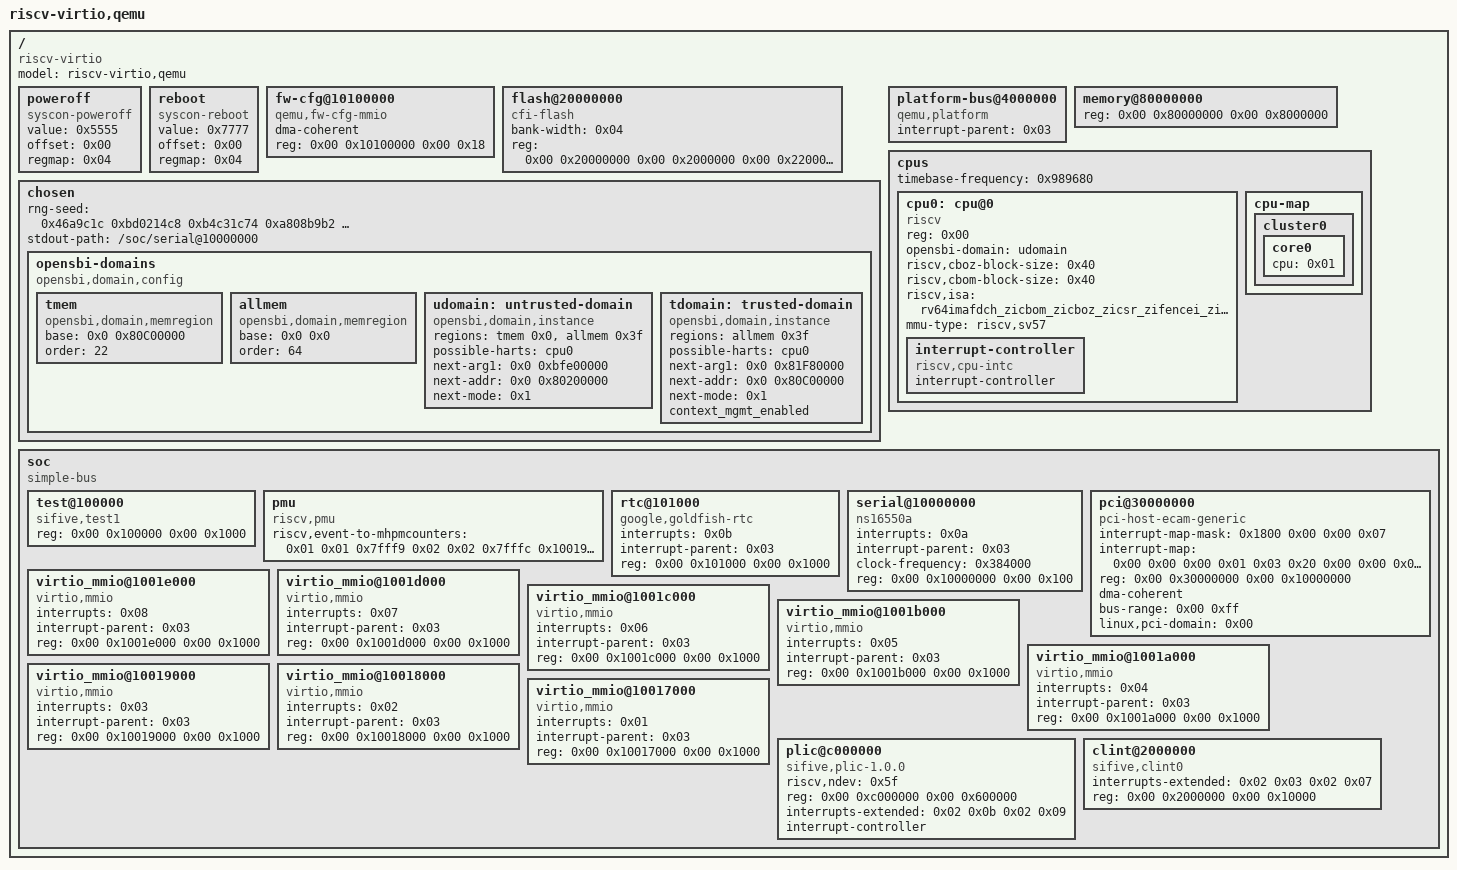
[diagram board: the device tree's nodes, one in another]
/dts-v1/;

/ {
	#address-cells = <0x02>;
	#size-cells = <0x02>;
	compatible = "riscv-virtio";
	model = "riscv-virtio,qemu";

	poweroff {
		value = <0x5555>;
		offset = <0x00>;
		regmap = <0x04>;
		compatible = "syscon-poweroff";
	};

	reboot {
		value = <0x7777>;
		offset = <0x00>;
		regmap = <0x04>;
		compatible = "syscon-reboot";
	};

	fw-cfg@10100000 {
		dma-coherent;
		reg = <0x00 0x10100000 0x00 0x18>;
		compatible = "qemu,fw-cfg-mmio";
	};

	flash@20000000 {
		bank-width = <0x04>;
		reg = <0x00 0x20000000 0x00 0x2000000 0x00 0x22000000 0x00 0x2000000>;
		compatible = "cfi-flash";
	};

	chosen {
		rng-seed = <0x46a9c1c 0xbd0214c8 0xb4c31c74 0xa808b9b2 0x50cb0d36 0x9aa9f04b 0x36ab14cc 0x835da7b>;
		stdout-path = "/soc/serial@10000000";
		opensbi-domains {
			compatible = "opensbi,domain,config";

			tmem: tmem {
				compatible = "opensbi,domain,memregion";
				base = <0x0 0x80C00000>;
				order = <22>;   // 4M
			};

			allmem: allmem {
				compatible = "opensbi,domain,memregion";
				base = <0x0 0x0>;
				order = <64>;
			};

			udomain: untrusted-domain {
				compatible = "opensbi,domain,instance";
				regions = <&tmem 0x0>, <&allmem 0x3f>;
				possible-harts = <&cpu0>;
				next-arg1 = <0x0 0xbfe00000>;
				next-addr = <0x0 0x80200000>;
				next-mode = <0x1>;
			};

			tdomain: trusted-domain {
				compatible = "opensbi,domain,instance";
				regions = <&allmem 0x3f>;
				possible-harts = <&cpu0>;
				next-arg1 = <0x0 0x81F80000>;
				next-addr = <0x0 0x80C00000>;
				next-mode = <0x1>;
                context_mgmt_enabled;
			};
		};
	};

	platform-bus@4000000 {
		interrupt-parent = <0x03>;
		ranges = <0x00 0x00 0x4000000 0x2000000>;
		#address-cells = <0x01>;
		#size-cells = <0x01>;
		compatible = "qemu,platform\0simple-bus";
	};

	memory@80000000 {
		device_type = "memory";
		reg = <0x00 0x80000000 0x00 0x8000000>;
	};

	cpus {
		#address-cells = <0x01>;
		#size-cells = <0x00>;
		timebase-frequency = <0x989680>;

		cpu0: cpu@0 {
			phandle = <0x01>;
			device_type = "cpu";
			reg = <0x00>;
			status = "okay";
			compatible = "riscv";
			opensbi-domain = <&udomain>;
			riscv,cboz-block-size = <0x40>;
			riscv,cbom-block-size = <0x40>;
			riscv,isa = "rv64imafdch_zicbom_zicboz_zicsr_zifencei_zihintpause_zawrs_zfa_zca_zcd_zba_zbb_zbc_zbs_sstc_svadu";
			mmu-type = "riscv,sv57";

			interrupt-controller {
				#interrupt-cells = <0x01>;
				interrupt-controller;
				compatible = "riscv,cpu-intc";
				phandle = <0x02>;
			};
		};

		cpu-map {

			cluster0 {

				core0 {
					cpu = <0x01>;
				};
			};
		};
	};

	soc {
		#address-cells = <0x02>;
		#size-cells = <0x02>;
		compatible = "simple-bus";
		ranges;

		test@100000 {
			phandle = <0x04>;
			reg = <0x00 0x100000 0x00 0x1000>;
			compatible = "sifive,test1\0sifive,test0\0syscon";
		};

		pmu {
			riscv,event-to-mhpmcounters = <0x01 0x01 0x7fff9 0x02 0x02 0x7fffc 0x10019 0x10019 0x7fff8 0x1001b 0x1001b 0x7fff8 0x10021 0x10021 0x7fff8>;
			compatible = "riscv,pmu";
		};

		rtc@101000 {
			interrupts = <0x0b>;
			interrupt-parent = <0x03>;
			reg = <0x00 0x101000 0x00 0x1000>;
			compatible = "google,goldfish-rtc";
		};

		serial@10000000 {
			interrupts = <0x0a>;
			interrupt-parent = <0x03>;
			clock-frequency = <0x384000>;
			reg = <0x00 0x10000000 0x00 0x100>;
			compatible = "ns16550a";
		};

		pci@30000000 {
			interrupt-map-mask = <0x1800 0x00 0x00 0x07>;
			interrupt-map = <0x00 0x00 0x00 0x01 0x03 0x20 0x00 0x00 0x00 0x02 0x03 0x21 0x00 0x00 0x00 0x03 0x03 0x22 0x00 0x00 0x00 0x04 0x03 0x23 0x800 0x00 0x00 0x01 0x03 0x21 0x800 0x00 0x00 0x02 0x03 0x22 0x800 0x00 0x00 0x03 0x03 0x23 0x800 0x00 0x00 0x04 0x03 0x20 0x1000 0x00 0x00 0x01 0x03 0x22 0x1000 0x00 0x00 0x02 0x03 0x23 0x1000 0x00 0x00 0x03 0x03 0x20 0x1000 0x00 0x00 0x04 0x03 0x21 0x1800 0x00 0x00 0x01 0x03 0x23 0x1800 0x00 0x00 0x02 0x03 0x20 0x1800 0x00 0x00 0x03 0x03 0x21 0x1800 0x00 0x00 0x04 0x03 0x22>;
			ranges = <0x1000000 0x00 0x00 0x00 0x3000000 0x00 0x10000 0x2000000 0x00 0x40000000 0x00 0x40000000 0x00 0x40000000 0x3000000 0x04 0x00 0x04 0x00 0x04 0x00>;
			reg = <0x00 0x30000000 0x00 0x10000000>;
			dma-coherent;
			bus-range = <0x00 0xff>;
			linux,pci-domain = <0x00>;
			device_type = "pci";
			compatible = "pci-host-ecam-generic";
			#size-cells = <0x02>;
			#interrupt-cells = <0x01>;
			#address-cells = <0x03>;
		};

		virtio_mmio@1001e000 {
			interrupts = <0x08>;
			interrupt-parent = <0x03>;
			reg = <0x00 0x1001e000 0x00 0x1000>;
			compatible = "virtio,mmio";
		};

		virtio_mmio@1001d000 {
			interrupts = <0x07>;
			interrupt-parent = <0x03>;
			reg = <0x00 0x1001d000 0x00 0x1000>;
			compatible = "virtio,mmio";
		};

		virtio_mmio@1001c000 {
			interrupts = <0x06>;
			interrupt-parent = <0x03>;
			reg = <0x00 0x1001c000 0x00 0x1000>;
			compatible = "virtio,mmio";
		};

		virtio_mmio@1001b000 {
			interrupts = <0x05>;
			interrupt-parent = <0x03>;
			reg = <0x00 0x1001b000 0x00 0x1000>;
			compatible = "virtio,mmio";
		};

		virtio_mmio@1001a000 {
			interrupts = <0x04>;
			interrupt-parent = <0x03>;
			reg = <0x00 0x1001a000 0x00 0x1000>;
			compatible = "virtio,mmio";
		};

		virtio_mmio@10019000 {
			interrupts = <0x03>;
			interrupt-parent = <0x03>;
			reg = <0x00 0x10019000 0x00 0x1000>;
			compatible = "virtio,mmio";
		};

		virtio_mmio@10018000 {
			interrupts = <0x02>;
			interrupt-parent = <0x03>;
			reg = <0x00 0x10018000 0x00 0x1000>;
			compatible = "virtio,mmio";
		};

		virtio_mmio@10017000 {
			interrupts = <0x01>;
			interrupt-parent = <0x03>;
			reg = <0x00 0x10017000 0x00 0x1000>;
			compatible = "virtio,mmio";
		};

		plic@c000000 {
			phandle = <0x03>;
			riscv,ndev = <0x5f>;
			reg = <0x00 0xc000000 0x00 0x600000>;
			interrupts-extended = <0x02 0x0b 0x02 0x09>;
			interrupt-controller;
			compatible = "sifive,plic-1.0.0\0riscv,plic0";
			#address-cells = <0x00>;
			#interrupt-cells = <0x01>;
		};

		clint@2000000 {
			interrupts-extended = <0x02 0x03 0x02 0x07>;
			reg = <0x00 0x2000000 0x00 0x10000>;
			compatible = "sifive,clint0\0riscv,clint0";
		};
	};
};
